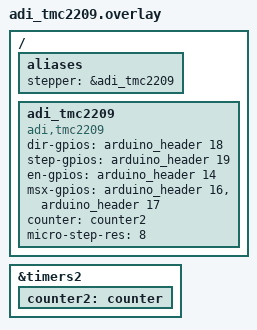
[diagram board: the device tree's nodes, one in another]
/*
 * Copyright (c) 2025 Navimatix GmbH
 * SPDX-License-Identifier: Apache-2.0
 */

#include <zephyr/dt-bindings/gpio/gpio.h>

/ {
	aliases {
		stepper =  &adi_tmc2209;
	};
};

/ {
	adi_tmc2209: adi_tmc2209 {
		status = "okay";
		compatible = "adi,tmc2209";

		dir-gpios = <&arduino_header 18 0>; /* D12 */
		step-gpios = <&arduino_header 19 0>; /* D13 */
		en-gpios  = <&arduino_header 14 0>; /* D8 */
		msx-gpios = <&arduino_header 16 GPIO_ACTIVE_HIGH>, /* D10 */
			<&arduino_header 17 GPIO_ACTIVE_HIGH>; /* D11 */
		counter = <&counter2>;
		micro-step-res = <8>;
	};
};

&timers2 {
	status = "okay";
	counter2: counter {
		status = "okay";
	};
};
